# ecc_reva_me21 register map
Registers are access not given, no defined reset value unless marked. A register's access mark holds for its fields unless they carry their own. Offsets are from the block's base; lines under a group give offsets from that group; [hi:lo] are bit positions; {n}, {i} and the like mark numbered series; 'fields as' and 'values as' point back to an identical list; <NAME> marks a mode.

## Memory map
0x40105400 ECC size 0x400 — Error Correction Code

## ECC — Error Correction Code
Base 0x40105400
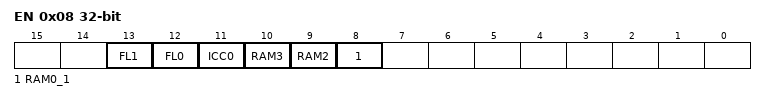
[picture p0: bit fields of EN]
0x08 EN — ECC Enable Register
  [all] fields
    0=dis (disabled); 1=en (enabled)
  [13] FL1 — Flash 1 ECC Enable.
  [12] FL0 — Flash 0 ECC Enable.
  [11] ICC0 — Instruction Cache 0 ECC Enable.
  [10] RAM3 — System RAM3 ECC Enable.
  [9] RAM2 — System RAM2 ECC Enable.
  [8] RAM0_1 — System RAM0 and RAM1 ECC Enable.
